# STM32U031xx register map
File version: 1.0
Registers are 32-bit, read-write, reset 0x0 unless marked. A register's access mark holds for its fields unless they carry their own. Offsets are from the block's base; [hi:lo] are bit positions; {n}, {i} and the like mark numbered series.

## EXTI — Asynch Interrupt/Event Controller (EXTI)
Base 0x40021800
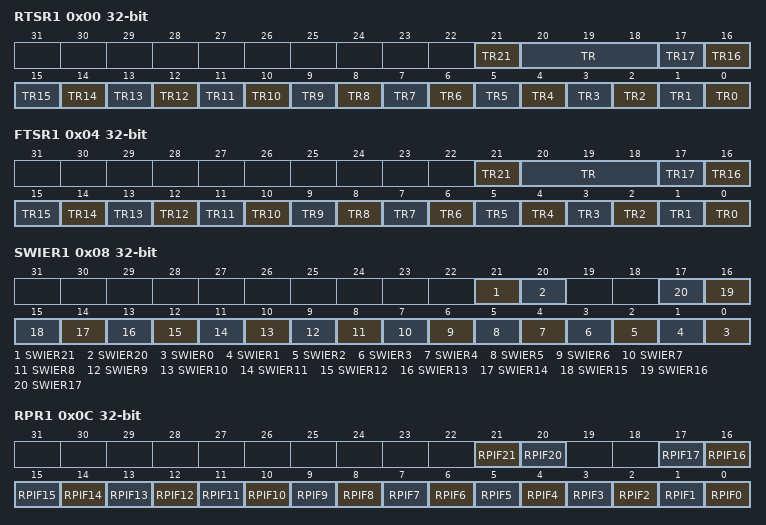
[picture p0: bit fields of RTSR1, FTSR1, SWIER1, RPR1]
0x00 RTSR1 — EXTI Rising Trigger Selection Register 1
  [21] TR21 — Rising trigger event configuration bit of line 21
  [20:18] TR — Rising trigger event configuration bit
  [n] TR{n} (n=0..17) — Rising trigger event configuration bit of line {n}
0x04 FTSR1 — EXTI Falling Trigger Selection Register 1
  [21] TR21 — Falling trigger event configuration bit of line 21
  [20:18] TR — Falling trigger event configuration bit
  [n] TR{n} (n=0..17) — Falling trigger event configuration bit of line {n}
0x08 SWIER1 — EXTI Software Interrupt event Register 1
  [21] SWIER21 — Software Interrupt on line 21
  [20] SWIER20 — Software Interrupt on line 20
  [n] SWIER{n} (n=0..17) — Software Interrupt on line {n}
0x0C RPR1 — EXTI Rising Pending Register 1
  [21] RPIF21 — Rising Pending Interrupt Flag on line 21
  [20] RPIF20 — Rising Pending Interrupt Flag on line 20
  [n] RPIF{n} (n=0..17) — Rising Pending Interrupt Flag on line {n}
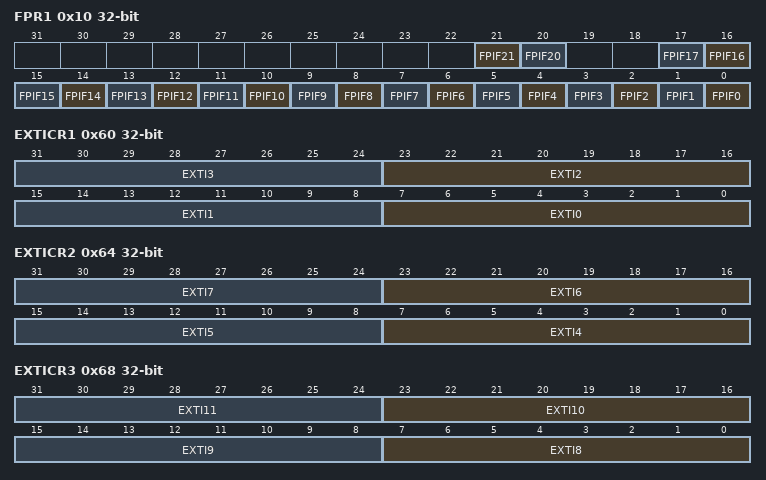
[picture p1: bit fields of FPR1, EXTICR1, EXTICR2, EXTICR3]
0x10 FPR1 — EXTI Falling Pending Register 1
  [21] FPIF21 — Falling Pending Interrupt Flag on line 21
  [20] FPIF20 — Falling Pending Interrupt Flag on line 20
  [n] FPIF{n} (n=0..17) — Falling Pending Interrupt Flag on line {n}
0x60 EXTICR1 — EXIT External Interrupt Configuration Register, 0x60 -- 0x6C
  [8n+7:8n] EXTI{n} (n=0..3) — EXTI {n} configuration
0x64 EXTICR2 — EXIT External Interrupt Configuration Register, 0x60 -- 0x6C
  [8n-25:8n-32] EXTI{n} (n=4..7) — EXTI {n} configuration
0x68 EXTICR3 — EXIT External Interrupt Configuration Register, 0x60 -- 0x6C
  [8n-57:8n-64] EXTI{n} (n=8..11) — EXTI {n} configuration
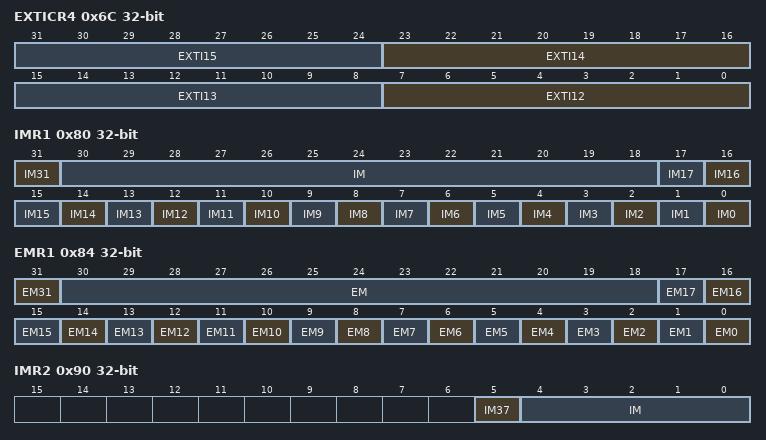
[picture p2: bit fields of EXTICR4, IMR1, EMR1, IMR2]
0x6C EXTICR4 — EXIT External Interrupt Configuration Register, 0x60 -- 0x6C
  [8n-89:8n-96] EXTI{n} (n=12..15) — EXTI {n} configuration
0x80 IMR1 — EXTI Interrupt Mask Register 1
  [31] IM31 — Interrupt Mask on line 31
  [30:18] IM — Interrupt Mask
  [n] IM{n} (n=0..17) — Interrupt Mask on line {n}
0x84 EMR1 — EXTI Event Mask Register 1
  [31] EM31 — Event Mask on line 31
  [30:18] EM — Event Mask
  [n] EM{n} (n=0..17) — Event Mask on line {n}
0x90 IMR2 — EXTI Interrupt Mask Register 2
  [5] IM37 — Interrupt Mask on line 37
  [4:0] IM — Interrupt Mask
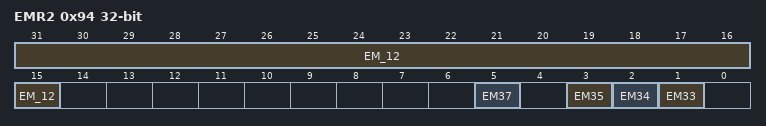
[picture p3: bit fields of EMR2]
0x94 EMR2 — EXTI Event Mask Register 2
  [31:15] EM_12 — Event Mask
  [5] EM37 — Event Mask on line 37
  [3] EM35 — Event Mask on line 35
  [2] EM34 — Event Mask on line 34
  [1] EM33 — Event Mask on line 33

## FLASH — FLASH Registers
Base 0x40022000
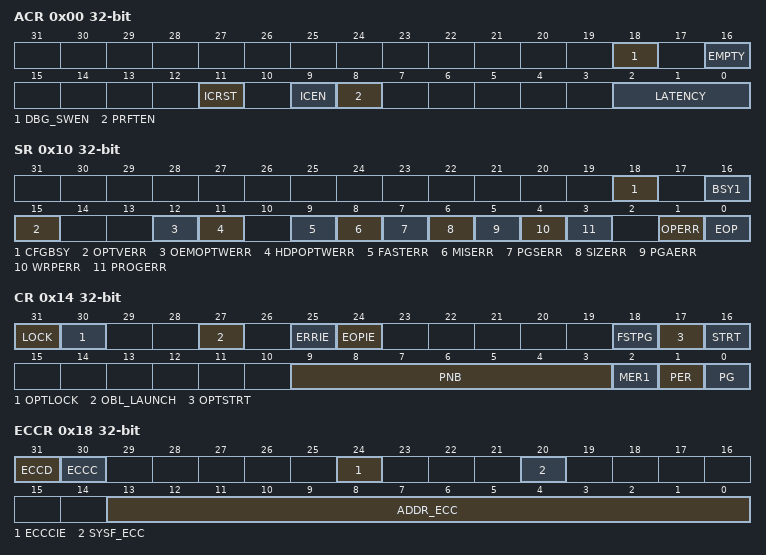
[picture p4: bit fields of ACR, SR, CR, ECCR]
0x00 ACR — FLASH Access Control register
  [18] DBG_SWEN
  [16] EMPTY
  [11] ICRST
  [9] ICEN
  [8] PRFTEN
  [2:0] LATENCY
    0=FLASH Zero Latency cycle; 1=FLASH One Latency cycle; 2=FLASH Two wait states
0x08 KEYR — FLASH Key register
0x0C OPTKEYR — FLASH Option Key register
0x10 SR — FLASH Status register
  [18] CFGBSY, [16] BSY1, [15] OPTVERR, [12] OEMOPTWERR, [11] HDPOPTWERR, [9] FASTERR, [8] MISERR, [7] PGSERR, [6] SIZERR, [5] PGAERR, [4] WRPERR, [3] PROGERR, [1] OPERR, [0] EOP
0x14 CR — FLASH Control register
  [31] LOCK, [30] OPTLOCK, [27] OBL_LAUNCH, [25] ERRIE, [24] EOPIE, [18] FSTPG, [17] OPTSTRT, [16] STRT, [9:3] PNB, [2] MER1, [1] PER, [0] PG
0x18 ECCR — FLASH ECC register
  [31] ECCD, [30] ECCC, [24] ECCCIE, [20] SYSF_ECC, [13:0] ADDR_ECC
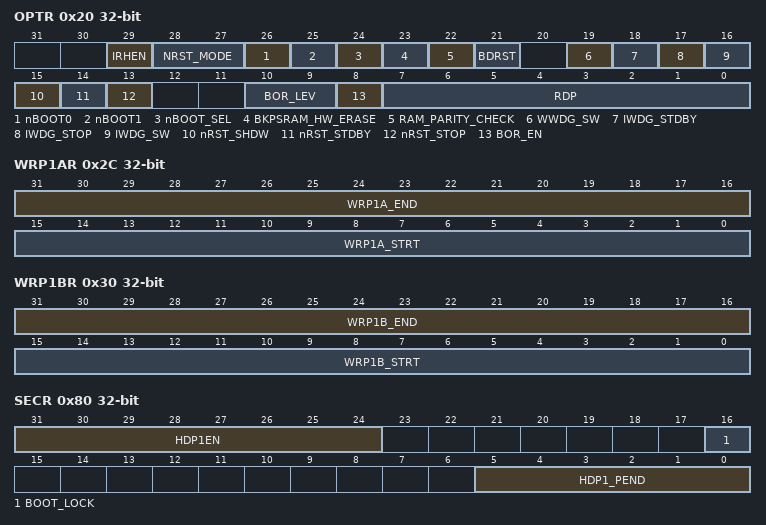
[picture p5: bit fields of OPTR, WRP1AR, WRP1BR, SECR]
0x20 OPTR — FLASH Option register
  [29] IRHEN, [28:27] NRST_MODE, [26] nBOOT0, [25] nBOOT1, [24] nBOOT_SEL, [23] BKPSRAM_HW_ERASE, [22] RAM_PARITY_CHECK, [21] BDRST, [19] WWDG_SW, [18] IWDG_STDBY, [17] IWDG_STOP, [16] IWDG_SW, [15] nRST_SHDW, [14] nRST_STDBY, [13] nRST_STOP, [10:9] BOR_LEV, [8] BOR_EN, [7:0] RDP
0x2C WRP1AR — FLASH Bank WRP area A address register
  [31:16] WRP1A_END, [15:0] WRP1A_STRT
0x30 WRP1BR — FLASH Bank WRP area B address register
  [31:16] WRP1B_END, [15:0] WRP1B_STRT
0x80 SECR — FLASH Security option register
  [31:24] HDP1EN, [16] BOOT_LOCK, [5:0] HDP1_PEND
{0x88+4i} OEM1KEYW{i}R (i=0..3) — FLASH OEM1 key register {i+1}
{0x98+4i} OEM2KEYW{i}R (i=0..3) — FLASH OEM2 key register {i+5}
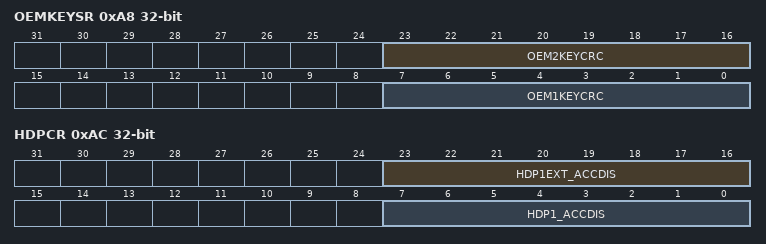
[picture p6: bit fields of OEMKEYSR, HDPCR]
0xA8 OEMKEYSR — FLASH OEM key status register
  [23:16] OEM2KEYCRC, [7:0] OEM1KEYCRC
0xAC HDPCR — FLASH HDP control register
  [23:16] HDP1EXT_ACCDIS, [7:0] HDP1_ACCDIS
0xB0 HDPEXTR — FLASH HDP extension register
  [5:0] HDP1_EXT
